# A31S13x register map
Vendor: VENDOR ABOV Semiconductor Co., Ltd.; Series: A31S13x; File version: 1.0
CPU: CM0+ r0p1, little endian, no MPU, no FPU, VTOR, 2 interrupt priority bits
Registers are 32-bit, read-write, reset 0x0 unless marked. A register's access mark holds for its fields unless they carry their own. Offsets are from the block's base; [hi:lo] are bit positions.

## WDT — Watch-Dog Timer
Base 0x40001A00
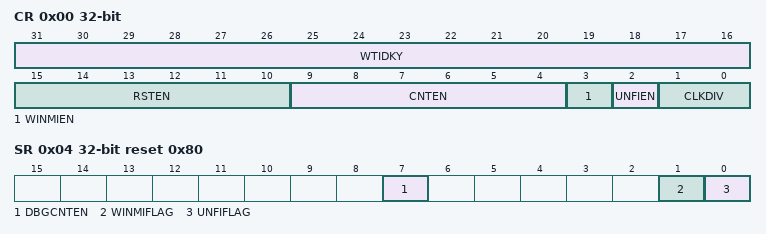
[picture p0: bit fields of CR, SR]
0x00 CR — Watch-Dog Timer Control Register
  [31:16] WTIDKY wo — Write Identification Key (0x5a69)
    0x5A69=Value (Key Value (0x5a69))
  [15:10] RSTEN — Watch-Dog Timer Reset Enable
    37=Disable Watch-Dog Timer reset. (0x25); 0=Enable Watch-Dog Timer reset
  [9:4] CNTEN — Watch-Dog Timer Counter Enable
    26=Disable Watch-Dog Timer counter. (0x1a); 0=Enable Watch-Dog Timer counter
  [3] WINMIEN — Watch-Dog Timer Window Match Interrupt Enable
    0=Disable window data match interrupt; 1=Enable window data match interrupt
  [2] UNFIEN — Watch-Dog Timer Underflow Interrupt Enable
    0=Disable Watch-Dog Timer underflow interrupt; 1=Enable Watch-Dog Timer underflow interrupt
  [1:0] CLKDIV — Watch-Dog Timer Clock Divider
    0=fWDT4; 1=fWDT16; 2=fWDT64; 3=fWDT256
0x04 SR reset 0x80 — Watch-Dog Timer Status Register
  [7] DBGCNTEN — Watch-Dog Timer Counter Enable When the core is halted in debug mode
    0=Run (The Watch-Dog Timer counter continues even if the core is halted); 1=Stop (The Watch-Dog Timer counter is stopped when the core is halted)
  [1] WINMIFLAG — Watch-Dog Timer Window Match Interrupt Flag
    0=No request occurred; 1=Request occurred
  [0] UNFIFLAG — Watch-Dog Timer Underflow Interrupt Flag
    0=No request occurred; 1=Request occurred
0x08 DR reset 0xFFF — Watch-Dog Timer Data Register
  [23:0] DATA — Watch-Dog Timer Data
0x0C CNT ro reset 0xFFF — Watch-Dog Timer Counter Register
  [23:0] CNT — Watch-Dog Timer Counter
0x10 WINDR reset 0x1FFF — Watch-Dog Timer Window Data Register
  [23:0] WDATA — Watch-Dog Timer Window Data
0x14 CNTR wo — Watch-Dog Timer Counter Reload Register
  [7:0] CNTR — Watch-Dog Timer Counter Reload
    106=Reload the WDTDR value to Watch-Dog Timer counter and re-start; 0=NoEffect

## WT — Watch Timer
Base 0x40002000
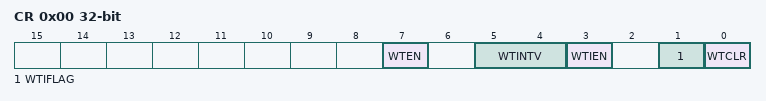
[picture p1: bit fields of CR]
0x00 CR — Watch Timer Control Register
  [7] WTEN — Watch Timer Operation Enable
    0=Disable watch timer operation; 1=Enable watch timer operation
  [5:4] WTINTV — Watch Timer Interval Selection
    0=fWT2Pow7 (fWT/2^7); 1=fWT2Pow13 (fWT/2^13); 2=fWT2Pow14 (fWT/2^14); 3=fWT2Pow14DR (fWT/(2^14x(WTDR value + 1)))
  [3] WTIEN — Watch Timer Interrupt Enable
    0=Disable watch timer interrupt; 1=Enable watch timer interrupt
  [1] WTIFLAG — Watch Timer Interrupt Flag
    0=No request occurred; 1=Request occurred
  [0] WTCLR — Watch Timer Counter and Divider Clear
    0=NoEffect; 1=Clear the counter and divider. (Automatically cleared to '0b' after operation)
0x04 DR reset 0xFFF — Watch Timer Data Register
  [11:0] WTDATA — Watch Timer Data
0x08 CNT ro — Watch Timer Counter Register
  [11:0] CNT — Watch Timer Counter

## TIMER1n — Timer/Counter 1n
Base 0x51000000
Same registers: TIMER10 0x40002100, TIMER11 0x40002200, TIMER12 0x40002300, TIMER13 0x40002700, TIMER14 0x40002800, TIMER15 0x40002900
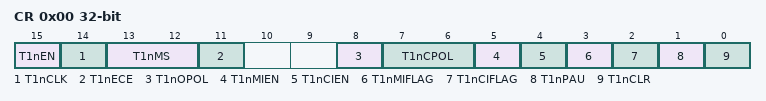
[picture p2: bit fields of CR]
0x00 CR — TIMER1n Control Register
  [15] T1nEN — TIMER1n Operation Enable
  [14] T1nCLK — TIMER1n Clock Selection
  [13:12] T1nMS — TIMER1n Operation Mode Selection
  [11] T1nECE — TIMER1n External Clock Edge Selection
  [8] T1nOPOL — TIMER1n Output Polarity Selection
  [7:6] T1nCPOL — TIMER1n Capture Polarity Selection
  [5] T1nMIEN — TIMER1n Match Interrupt Enable
  [4] T1nCIEN — TIMER1n Capture Interrupt Enable
  [3] T1nMIFLAG — TIMER1n Match Interrupt Flag
  [2] T1nCIFLAG — TIMER1n Capture Interrupt Flag
  [1] T1nPAU — TIMER1n Counter Temporary Pause Control
  [0] T1nCLR — TIMER1n Counter and Prescaler Clear
0x04 ADR reset 0xFFFF — TIMER1n A Data Register
  [15:0] ADATA — TIMER1n A Data
0x08 BDR reset 0xFFFF — TIMER1n B Data Register
  [15:0] BDATA — TIMER1n B Data
0x0C CAPDR ro — TIMER1n Capture Data Register
  [15:0] CAPD — TIMER1n Capture Data
0x10 PREDR reset 0xFFF — TIMER1n Prescaler Data Register
  [11:0] PRED — TIMER1n Prescaler Data
0x14 CNT ro — TIMER1n Counter Register
  [15:0] CNT — TIMER1n Counter
